# nrf54h20_engb_radiocore register map
Vendor: Nordic Semiconductor; Series: nRF54h; File version: 1
CPU: CM33 r0p4, little endian, MPU, FPU, 3 interrupt priority bits, 480 interrupts, 8 SAU regions
Registers are 32-bit, read-write, reset 0x0 unless marked. A register's access mark holds for its fields unless they carry their own. Offsets are from the block's base; [hi:lo] are bit positions; {n}, {i} and the like mark numbered series; 'fields as' and 'values as' point back to an identical list.

## TIMER020_NS — Timer/Counter 0
Base 0x43028000
Same registers: TIMER021_NS 0x43029000, TIMER022_NS 0x4302A000, GLOBAL_TIMER120_NS 0x4F8E2000, GLOBAL_TIMER121_NS 0x4F8E3000, GLOBAL_TIMER130_NS 0x4F9A2000, GLOBAL_TIMER131_NS 0x4F9A3000, GLOBAL_TIMER132_NS 0x4F9B2000, GLOBAL_TIMER133_NS 0x4F9B3000, GLOBAL_TIMER134_NS 0x4F9C2000, GLOBAL_TIMER135_NS 0x4F9C3000, GLOBAL_TIMER136_NS 0x4F9D2000, GLOBAL_TIMER137_NS 0x4F9D3000, TIMER020_S 0x53028000, TIMER021_S 0x53029000, TIMER022_S 0x5302A000, GLOBAL_TIMER120_S 0x5F8E2000, GLOBAL_TIMER121_S 0x5F8E3000, GLOBAL_TIMER130_S 0x5F9A2000, GLOBAL_TIMER131_S 0x5F9A3000, GLOBAL_TIMER132_S 0x5F9B2000, GLOBAL_TIMER133_S 0x5F9B3000, GLOBAL_TIMER134_S 0x5F9C2000, GLOBAL_TIMER135_S 0x5F9C3000, GLOBAL_TIMER136_S 0x5F9D2000, GLOBAL_TIMER137_S 0x5F9D3000
0x00 TASKS_START wo — Start Timer
  [0] TASKS_START
    1=Trigger task
0x04 TASKS_STOP wo — Stop Timer
  [0] TASKS_STOP
    1=Trigger task
0x08 TASKS_COUNT wo — Increment Timer (Counter mode only)
  [0] TASKS_COUNT
    1=Trigger task
0x0C TASKS_CLEAR wo — Clear time
  [0] TASKS_CLEAR
    1=Trigger task
0x10 TASKS_SHUTDOWN wo — Deprecated register - Shut down timer
  [0] TASKS_SHUTDOWN — Deprecated field - Shut down timer
    1=Trigger task
{0x40+4i} TASKS_CAPTURE[{i}] (i=0..7) wo — Description collection: Capture Timer value to CC[n] register
  [0] TASKS_CAPTURE — Capture Timer value to CC[n] register
    1=Trigger task
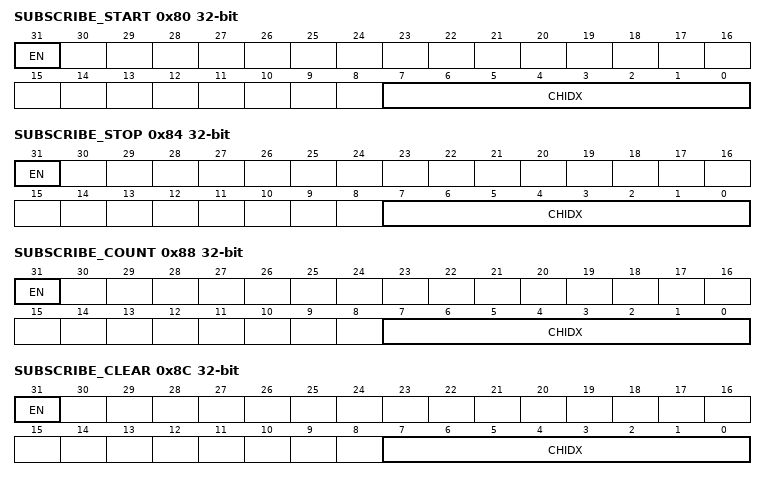
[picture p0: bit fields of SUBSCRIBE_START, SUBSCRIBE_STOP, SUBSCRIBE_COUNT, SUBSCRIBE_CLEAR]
0x80 SUBSCRIBE_START — Subscribe configuration for task START
  [31] EN
    0=Disabled (Disable subscription); 1=Enabled (Enable subscription)
  [7:0] CHIDX — DPPI channel that task START will subscribe to
0x84 SUBSCRIBE_STOP — Subscribe configuration for task STOP
  [31] EN
    values as SUBSCRIBE_START.EN
  [7:0] CHIDX — DPPI channel that task STOP will subscribe to
0x88 SUBSCRIBE_COUNT — Subscribe configuration for task COUNT
  [31] EN
    values as SUBSCRIBE_START.EN
  [7:0] CHIDX — DPPI channel that task COUNT will subscribe to
0x8C SUBSCRIBE_CLEAR — Subscribe configuration for task CLEAR
  [31] EN
    values as SUBSCRIBE_START.EN
  [7:0] CHIDX — DPPI channel that task CLEAR will subscribe to
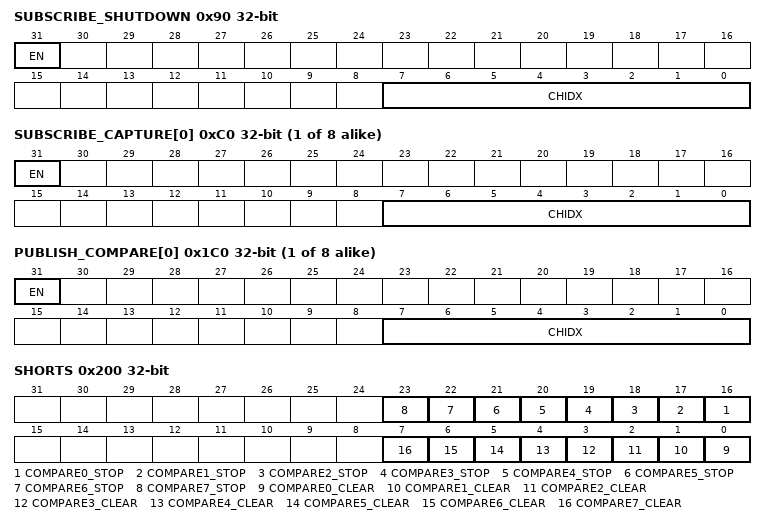
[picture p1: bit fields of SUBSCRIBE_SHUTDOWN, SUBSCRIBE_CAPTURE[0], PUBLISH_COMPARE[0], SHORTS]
0x90 SUBSCRIBE_SHUTDOWN — Deprecated register - Subscribe configuration for task SHUTDOWN
  [31] EN
    values as SUBSCRIBE_START.EN
  [7:0] CHIDX — DPPI channel that task SHUTDOWN will subscribe to
{0xC0+4i} SUBSCRIBE_CAPTURE[{i}] (i=0..7) — Description collection: Subscribe configuration for task CAPTURE[n]
  [31] EN
    values as SUBSCRIBE_START.EN
  [7:0] CHIDX — DPPI channel that task CAPTURE[n] will subscribe to
{0x140+4i} EVENTS_COMPARE[{i}] (i=0..7) — Description collection: Compare event on CC[n] match
  [0] EVENTS_COMPARE — Compare event on CC[n] match
    0=NotGenerated (Event not generated); 1=Generated (Event generated)
{0x1C0+4i} PUBLISH_COMPARE[{i}] (i=0..7) — Description collection: Publish configuration for event COMPARE[n]
  [31] EN
    0=Disabled (Disable publishing); 1=Enabled (Enable publishing)
  [7:0] CHIDX — DPPI channel that event COMPARE[n] will publish to
0x200 SHORTS — Shortcuts between local events and tasks
  [all] fields
    0=Disabled (Disable shortcut); 1=Enabled (Enable shortcut)
  [n+16] COMPARE{n}_STOP (n=0..7) — Shortcut between event COMPARE[{n}] and task STOP
  [n] COMPARE{n}_CLEAR (n=0..7) — Shortcut between event COMPARE[{n}] and task CLEAR
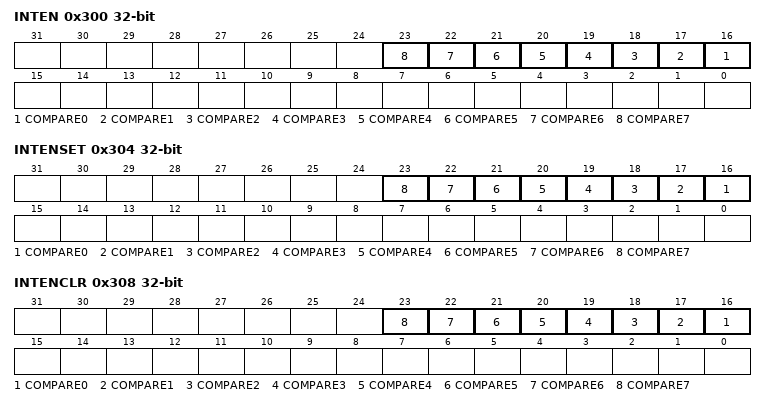
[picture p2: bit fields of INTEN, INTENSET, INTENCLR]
0x300 INTEN — Enable or disable interrupt
  [all] fields
    0=Disabled; 1=Enabled
  [n+16] COMPARE{n} (n=0..7) — Enable or disable interrupt for event COMPARE[{n}]
0x304 INTENSET — Enable interrupt
  [all] fields
    on read: 0=Disabled (Read: Disabled); 1=Enabled (Read: Enabled) | on write: 1=Set (Enable)
  [n+16] COMPARE{n} (n=0..7) — Write '1' to enable interrupt for event COMPARE[{n}]
0x308 INTENCLR — Disable interrupt
  [all] fields
    on read: 0=Disabled (Read: Disabled); 1=Enabled (Read: Enabled) | on write: 1=Clear (Disable)
  [n+16] COMPARE{n} (n=0..7) — Write '1' to disable interrupt for event COMPARE[{n}]
0x500 MULTITIMERENABLE — Register doesn't do anything. Can be written and read, but has no functionality attached.
  [0] MULTITIMERENABLE
    0=DISABLE (Unspecified); 1=ENABLE (Unspecified)
0x504 MODE — Timer mode selection
  [1:0] MODE — Timer mode
    0=Timer (Select Timer mode); 1=Counter (Deprecated enumerator - Select Counter mode); 2=LowPowerCounter (Select Low Power Counter mode)
0x508 BITMODE — Configure the number of bits used by the TIMER
  [1:0] BITMODE — Timer bit width
    0=16 bit timer bit width; 1=08Bit (8 bit timer bit width); 2=24 bit timer bit width; 3=32 bit timer bit width
0x510 PRESCALER reset 0x4 — Timer prescaler register
  [3:0] PRESCALER — Prescaler value
{0x540+4i} CC[{i}] (i=0..7) — Description collection: Capture/Compare register n
  [31:0] CC — Capture/Compare value
{0x580+4i} ONESHOTEN[{i}] (i=0..7) — Description collection: Enable one-shot operation for Capture/Compare channel n
  [0] ONESHOTEN — Enable one-shot operation
    0=Disable one-shot operation; 1=Enable one-shot operation
